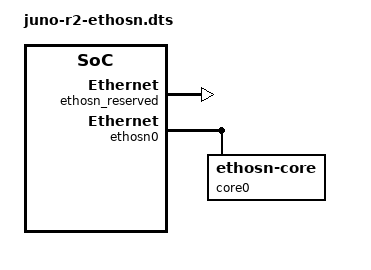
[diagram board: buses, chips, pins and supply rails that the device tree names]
/*
 *
 * (C) COPYRIGHT 2020-2021 Arm Limited.
 *
 * This program is free software and is provided to you under the terms of the
 * GNU General Public License version 2 as published by the Free Software
 * Foundation, and any use by you of this program is subject to the terms
 * of such GNU licence.
 *
 * This program is distributed in the hope that it will be useful,
 * but WITHOUT ANY WARRANTY; without even the implied warranty of
 * MERCHANTABILITY or FITNESS FOR A PARTICULAR PURPOSE. See the
 * GNU General Public License for more details.
 *
 * You should have received a copy of the GNU General Public License
 * along with this program; if not, you can access it online at
 * http://www.gnu.org/licenses/gpl-2.0.html.
 *
 * SPDX-License-Identifier: GPL-2.0-only
 *
 */

/include/ "juno-r2-ethosn.dtsi"

&ethosn_reserved {
	status = "okay";
};

&ethosn0 {
	reg = <0 0x6f300000 0 0x00100000>;
	memory-region = <&ethosn_reserved>;
	status = "okay";

	core0 {
		compatible = "ethosn-core";
		status = "okay";
	};
};
